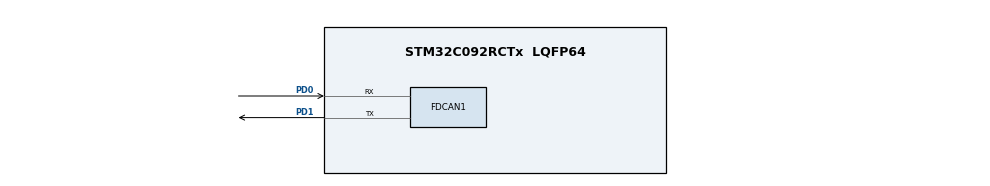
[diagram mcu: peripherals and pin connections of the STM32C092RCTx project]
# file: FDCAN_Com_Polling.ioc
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FDCAN1.AutoRetransmission=ENABLE
FDCAN1.CalculateBaudRateData=1000000
FDCAN1.CalculateBaudRateNominal=1000000
FDCAN1.CalculateTimeBitNominal=1000
FDCAN1.CalculateTimeQuantumNominal=20.833333333333332
FDCAN1.DataSyncJumpWidth=6
FDCAN1.DataTimeSeg1=17
FDCAN1.DataTimeSeg2=6
FDCAN1.FrameFormat=FDCAN_FRAME_FD_BRS
FDCAN1.NominalPrescaler=1
FDCAN1.NominalSyncJumpWidth=12
FDCAN1.NominalTimeSeg1=35
FDCAN1.NominalTimeSeg2=12
FDCAN1.StdFiltersNbr=1
FDCAN1.TransmitPause=ENABLE
Mcu.Family=STM32C0
Mcu.Name=STM32C092RCTx
Mcu.Package=LQFP64
NUCLEO-C092RC.BUTTON=2
NUCLEO-C092RC.LD1=true
NUCLEO-C092RC.LD2=true
NUCLEO-C092RC.VCP=true
PD0.Mode=FDCAN_Activate
PD0.Signal=FDCAN1_RX
PD1.Mode=FDCAN_Activate
PD1.Signal=FDCAN1_TX
ProjectManager.HeapSize=0x200
ProjectManager.StackSize=0x400
ProjectManager.TargetToolchain=STM32CubeIDE
RCC.ADCFreq_Value=48000000
RCC.AHBFreq_Value=48000000
RCC.CortexFreq_Value=48000000
RCC.EXTERNAL_CLOCK_VALUE=12288000
RCC.HCLKFreq_Value=48000000
RCC.HSE_VALUE=8000000
RCC.HSISYSCLKDivider=RCC_HSI_DIV1
RCC.HSI_VALUE=48000000
RCC.LSE_VALUE=32768
RCC.SYSCLKFreq_VALUE=48000000
VP_NUCLEO-C092RC_VS_BSP_COMMON.Mode=COMMON
board=NUCLEO-C092RC

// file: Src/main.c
/* USER CODE BEGIN Header */
/**
  ******************************************************************************
  * @file    FDCAN/FDCAN_Com_Polling/Src/main.c
  * @author  MCD Application Team
  * @brief   This sample code shows how to achieve Polling Process Communication
  *          between two FDCAN units.
  ******************************************************************************
  * @attention
  *
  * Copyright (c) 2024 STMicroelectronics.
  * All rights reserved.
  *
  * This software is licensed under terms that can be found in the LICENSE file
  * in the root directory of this software component.
  * If no LICENSE file comes with this software, it is provided AS-IS.
  *
  ******************************************************************************
  */
/* USER CODE END Header */
#include "main.h"

/* USER CODE BEGIN Includes */
#include <stdio.h>
/* USER CODE END Includes */

/* USER CODE BEGIN PD */
#define TX_ID          (0x111)   /* TX CAN message identifier    */
#define RX_ID          (0x222)   /* RX CAN message identifier    */
/* USER CODE END PD */

/* USER CODE BEGIN PM */
#define COUNTOF(BUFFER) (sizeof((BUFFER)) / sizeof(*(BUFFER)))
/* USER CODE END PM */

COM_InitTypeDef BspCOMInit;

FDCAN_HandleTypeDef hfdcan1;

/* USER CODE BEGIN PV */
FDCAN_RxHeaderTypeDef rxHeader;
FDCAN_TxHeaderTypeDef txHeader;
uint8_t rxData[16U];

// changed random hex to custom 16-byte text array
static const uint8_t txData[] = {'H', 'e', 'l', 'l', 'o', ' ', 'R', 'o',
                                 'd', 'r', 'i', 'g', 'o', '!', '\r', '\n'
                                };

/* USER CODE END PV */

void SystemClock_Config(void);
static void MX_GPIO_Init(void);
static void MX_FDCAN1_Init(void);
/* USER CODE BEGIN PFP */
static uint32_t BufferCmp8b(const uint8_t *pBuffer1, const uint8_t *pBuffer2, uint16_t BufferLength);

/* USER CODE END PFP */

int main(void)
{

  /* USER CODE BEGIN 1 */

  /* STM32C0xx HAL library initialization:
       - Configure the Flash prefetch
       - Systick timer is configured by default as source of time base, but user
         can eventually implement his proper time base source (a general purpose
         timer for example or other time source), keeping in mind that Time base
         duration should be kept 1ms since PPP_TIMEOUT_VALUEs are defined and
         handled in milliseconds basis.
       - Low Level Initialization
     */
  /* USER CODE END 1 */

  /* MCU Configuration--------------------------------------------------------*/

  /* Reset of all peripherals, Initializes the Flash interface and the Systick. */
  HAL_Init();

  /* Configure the system clock */
  SystemClock_Config();

  /* USER CODE BEGIN SysInit */
  /* Configure LED1 and LED2 */
  BSP_LED_Init(LED1);
  BSP_LED_Init(LED2);

  /* Configure User push-button in interrupt mode */
  BSP_PB_Init(BUTTON_USER, BUTTON_MODE_EXTI);

  /* USER CODE END SysInit */

  /* Initialize all configured peripherals */
  MX_GPIO_Init();
  MX_FDCAN1_Init();
  /* USER CODE BEGIN 2 */

  /* Configure reception filter to Rx FIFO 0 */
  FDCAN_FilterTypeDef        sFilterConfig;
  sFilterConfig.IdType       = FDCAN_STANDARD_ID;
  sFilterConfig.FilterIndex  = 0U;
  sFilterConfig.FilterType   = FDCAN_FILTER_MASK;
  sFilterConfig.FilterConfig = FDCAN_FILTER_TO_RXFIFO0;
  sFilterConfig.FilterID1    = TX_ID;
  sFilterConfig.FilterID2    = 0x7FF;
  if (HAL_FDCAN_ConfigFilter(&hfdcan1, &sFilterConfig) != HAL_OK)
  {
    Error_Handler();
  }

  /**
    *  Configure global filter:
    *    - Filter all remote frames with STD and EXT ID
    *    - Reject non matching frames with STD ID and EXT ID
    */
  if (HAL_FDCAN_ConfigGlobalFilter(&hfdcan1,
                                   FDCAN_REJECT, FDCAN_REJECT,
                                   FDCAN_FILTER_REMOTE, FDCAN_FILTER_REMOTE) != HAL_OK)
  {
    Error_Handler();
  }

  /* Prepare Tx message Header */
  txHeader.Identifier          = TX_ID;
  txHeader.IdType              = FDCAN_STANDARD_ID;
  txHeader.TxFrameType         = FDCAN_DATA_FRAME;
  txHeader.DataLength          = FDCAN_DLC_BYTES_16;
  txHeader.ErrorStateIndicator = FDCAN_ESI_ACTIVE;
  txHeader.BitRateSwitch       = FDCAN_BRS_ON;
  txHeader.FDFormat            = FDCAN_FD_CAN;
  txHeader.TxEventFifoControl  = FDCAN_NO_TX_EVENTS;
  txHeader.MessageMarker       = 0U;

  /**
    * Configure and enable Tx Delay Compensation, required for BRS mode.
    * TdcOffset default recommended value: DataTimeSeg1 * DataPrescaler
    * TdcFilter default recommended value: 0
    */
  if (HAL_FDCAN_ConfigTxDelayCompensation(&hfdcan1,
                                          (hfdcan1.Init.DataPrescaler * hfdcan1.Init.DataTimeSeg1), 0U) != HAL_OK)
  {
    Error_Handler();
  }

  if (HAL_FDCAN_EnableTxDelayCompensation(&hfdcan1) != HAL_OK)
  {
    Error_Handler();
  }

  /* Start FDCAN controller */
  if (HAL_FDCAN_Start(&hfdcan1) != HAL_OK)
  {
    Error_Handler();
  }
  /* USER CODE END 2 */

  /* Initialize leds */
  BSP_LED_Init(LED_GREEN);
  BSP_LED_Init(LED_BLUE);

  /* Initialize User push-button without interrupt mode. */
  BSP_PB_Init(BUTTON_USER, BUTTON_MODE_EXTI);

  /* Initialize COM1 port (115200, 8 bits (7-bit data + 1 stop bit), no parity */
  BspCOMInit.BaudRate   = 115200;
  BspCOMInit.WordLength = COM_WORDLENGTH_8B;
  BspCOMInit.StopBits   = COM_STOPBITS_1;
  BspCOMInit.Parity     = COM_PARITY_NONE;
  BspCOMInit.HwFlowCtl  = COM_HWCONTROL_NONE;
  if (BSP_COM_Init(COM1, &BspCOMInit) != BSP_ERROR_NONE)
  {
    Error_Handler();
  }

  /* Infinite loop */
  /* USER CODE BEGIN WHILE */
  while (1)
  {
    /* Polling mode: Wait for one message received */
    while (HAL_FDCAN_GetRxFifoFillLevel(&hfdcan1, FDCAN_RX_FIFO0) < 1U)
    {
      /* Do nothing, wait */
    }

    /* Retrieve Rx message from RX FIFO0 */
    if (HAL_FDCAN_GetRxMessage(&hfdcan1, FDCAN_RX_FIFO0, &rxHeader, rxData) != HAL_OK)
    {
      Error_Handler();
    }

    // recieved message print to USB cable
    printf("Message Received! ID: 0x%lX\r\n", rxHeader.Identifier);
    printf("Payload: %16.16s\r\n", rxData);

    /* Compare received RX message to expected data. Ignore if not matching. */
    if ((rxHeader.Identifier == RX_ID) &&
        (rxHeader.IdType     == FDCAN_STANDARD_ID) &&
        (rxHeader.DataLength == FDCAN_DLC_BYTES_16) &&
        (BufferCmp8b(txData, rxData, COUNTOF(rxData)) == 0U))
    {
      /* Turn LED1 on */
      BSP_LED_On(LED1);
    }
    /* USER CODE END WHILE */

  }
}

void SystemClock_Config(void)
{
  RCC_OscInitTypeDef RCC_OscInitStruct = {0};
  RCC_ClkInitTypeDef RCC_ClkInitStruct = {0};

  __HAL_FLASH_SET_LATENCY(FLASH_LATENCY_1);

  /** Initializes the RCC Oscillators according to the specified parameters
  * in the RCC_OscInitTypeDef structure.
  */
  RCC_OscInitStruct.OscillatorType = RCC_OSCILLATORTYPE_HSI;
  RCC_OscInitStruct.HSIState = RCC_HSI_ON;
  RCC_OscInitStruct.HSIDiv = RCC_HSI_DIV1;
  RCC_OscInitStruct.HSICalibrationValue = RCC_HSICALIBRATION_DEFAULT;
  if (HAL_RCC_OscConfig(&RCC_OscInitStruct) != HAL_OK)
  {
    Error_Handler();
  }

  /** Initializes the CPU, AHB and APB buses clocks
  */
  RCC_ClkInitStruct.ClockType = RCC_CLOCKTYPE_HCLK|RCC_CLOCKTYPE_SYSCLK
                              |RCC_CLOCKTYPE_PCLK1;
  RCC_ClkInitStruct.SYSCLKSource = RCC_SYSCLKSOURCE_HSI;
  RCC_ClkInitStruct.SYSCLKDivider = RCC_SYSCLK_DIV1;
  RCC_ClkInitStruct.AHBCLKDivider = RCC_HCLK_DIV1;
  RCC_ClkInitStruct.APB1CLKDivider = RCC_APB1_DIV1;

  if (HAL_RCC_ClockConfig(&RCC_ClkInitStruct, FLASH_LATENCY_1) != HAL_OK)
  {
    Error_Handler();
  }
}

static void MX_FDCAN1_Init(void)
{

  hfdcan1.Instance = FDCAN1;
  hfdcan1.Init.ClockDivider = FDCAN_CLOCK_DIV1;
  hfdcan1.Init.FrameFormat = FDCAN_FRAME_FD_BRS;
  hfdcan1.Init.Mode = FDCAN_MODE_NORMAL;
  hfdcan1.Init.AutoRetransmission = ENABLE;
  hfdcan1.Init.TransmitPause = ENABLE;
  hfdcan1.Init.ProtocolException = DISABLE;
  hfdcan1.Init.NominalPrescaler = 1;
  hfdcan1.Init.NominalSyncJumpWidth = 12;
  hfdcan1.Init.NominalTimeSeg1 = 35;
  hfdcan1.Init.NominalTimeSeg2 = 12;
  hfdcan1.Init.DataPrescaler = 1;
  hfdcan1.Init.DataSyncJumpWidth = 6;
  hfdcan1.Init.DataTimeSeg1 = 17;
  hfdcan1.Init.DataTimeSeg2 = 6;
  hfdcan1.Init.StdFiltersNbr = 1;
  hfdcan1.Init.ExtFiltersNbr = 0;
  hfdcan1.Init.TxFifoQueueMode = FDCAN_TX_FIFO_OPERATION;
  if (HAL_FDCAN_Init(&hfdcan1) != HAL_OK)
  {
    Error_Handler();
  }

}

static void MX_GPIO_Init(void)
{

  /* GPIO Ports Clock Enable */
  __HAL_RCC_GPIOD_CLK_ENABLE();

}

/* USER CODE BEGIN 4 */
extern UART_HandleTypeDef huart2;

// route printf to USB cable
int _write(int file, char *ptr, int len) {
    HAL_UART_Transmit(&huart2, (uint8_t*)ptr, len, HAL_MAX_DELAY);
    return len;
}

/**
  * @brief  BSP User push-button callback
  * @param  Button Specifies the pin connected EXTI line
  * @retval None.
  */
void BSP_PB_Callback(Button_TypeDef Button)
{
  if (Button == BUTTON_USER)
  {
    /* Turn LED1 off */
    BSP_LED_Off(LED1);

    /* Add message to TX FIFO */
    if (HAL_FDCAN_AddMessageToTxFifoQ(&hfdcan1, &txHeader, txData) != HAL_OK)
    {
      Error_Handler();
    }

    // transmit print message to USB cable
    printf("Adam's Board: Message Sent to CAN Bus!\r\n");

    /* Delay for simple button debounce */
    HAL_Delay(100U);
  }
}

/**
  * @brief  Compares two buffers.
  * @param  pBuffer1 buffer to be compared.
  * @param  pBuffer2 buffer to be compared.
  * @param  BufferLength: buffer's length.
  * @retval 0: pBuffer1 is identical to pBuffer2
  * @retval 1: pBuffer1 differs from pBuffer2
  */
static uint32_t BufferCmp8b(const uint8_t *pBuffer1, const uint8_t *pBuffer2, uint16_t BufferLength)
{
  while (BufferLength--)
  {
    if (*pBuffer1 != *pBuffer2)
    {
      return 1U;
    }

    pBuffer1++;
    pBuffer2++;
  }
  return 0U;
}
/* USER CODE END 4 */

void Error_Handler(void)
{
  /* USER CODE BEGIN Error_Handler_Debug */
  /* User can add his own implementation to report the HAL error return state */

  while (1)
  {
    /* Toggle LED2 on */
    BSP_LED_Toggle(LED2);

    /* 1s delay */
    HAL_Delay(1000U);
  }
  /* USER CODE END Error_Handler_Debug */
}
